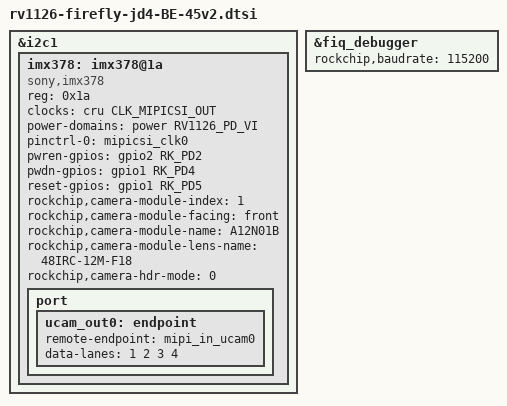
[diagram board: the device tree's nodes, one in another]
// SPDX-License-Identifier: (GPL-2.0+ OR MIT)
/*
 * Copyright (c) 2020 Rockchip Electronics Co., Ltd.
 */

#include "rv1126-firefly-jd4-BE-45.dtsi"

&i2c1 {
	//status = "okay";
	/delete-node/ os04a10@36;
	//clock-frequency = <400000>;

	imx378: imx378@1a {
		compatible = "sony,imx378";
		reg = <0x1a>;
		clocks = <&cru CLK_MIPICSI_OUT>;
		clock-names = "xvclk";
		power-domains = <&power RV1126_PD_VI>;
		pinctrl-names = "default";
		pinctrl-0 = <&mipicsi_clk0>;
		pwren-gpios= <&gpio2 RK_PD2 GPIO_ACTIVE_HIGH>;
		pwdn-gpios = <&gpio1 RK_PD4 GPIO_ACTIVE_HIGH>;
		reset-gpios = <&gpio1 RK_PD5 GPIO_ACTIVE_HIGH>;
		rockchip,camera-module-index = <1>;
		rockchip,camera-module-facing = "front";
		rockchip,camera-module-name = "A12N01B";
		rockchip,camera-module-lens-name = "48IRC-12M-F18";
		// NO_HDR:0 HDR_X2:5 HDR_X3:6
		rockchip,camera-hdr-mode = <0>;
		port {
			ucam_out0: endpoint {
				remote-endpoint = <&mipi_in_ucam0>;
				data-lanes = <1 2 3 4>;
			};
		};
	};
};

&fiq_debugger {
	//status = "okay";
	/* /delete-node/ fiq_debugger; */
	rockchip,baudrate = <115200>;  /* Only 115200 and 1500000 */	
};
